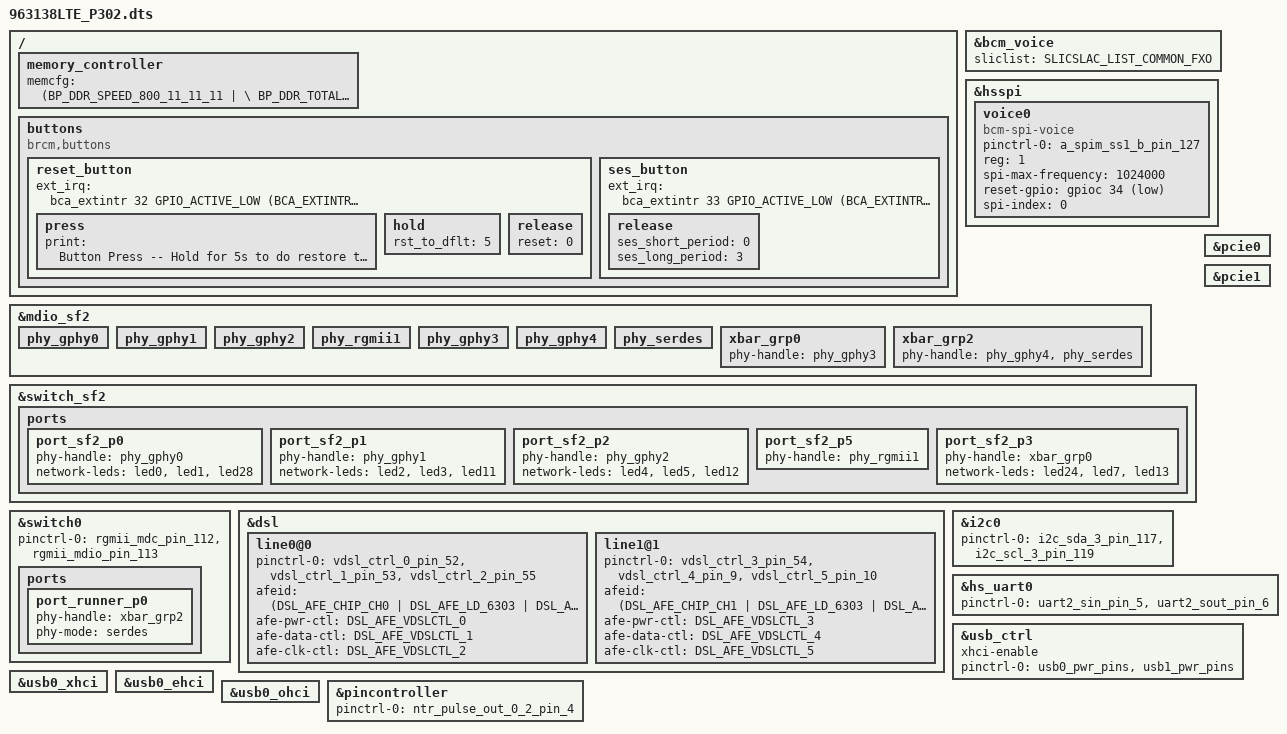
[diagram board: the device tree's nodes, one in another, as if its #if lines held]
#include "63138.dtsi"
#include "../bcm_voice.dtsi"
#include "963138LTE_leds.dtsi"

/ {
	memory_controller {
		memcfg = <(BP_DDR_SPEED_800_11_11_11   | \
			BP_DDR_TOTAL_SIZE_512MB  | \
			BP_DDR_DEVICE_WIDTH_16)>;
	};

	buttons {
		compatible = "brcm,buttons";
		reset_button {
			ext_irq = <&bca_extintr 32 GPIO_ACTIVE_LOW (BCA_EXTINTR_TYPE_LOW_LEVEL | BCA_EXTINTR_TYPE_SENSE_LEVEL)>;
			press {
				print = "Button Press -- Hold for 5s to do restore to default";
			};
			hold {
				rst_to_dflt = <5>;
			};
			release {
				reset = <0>;
			};	
		};
		ses_button {
			ext_irq = <&bca_extintr 33 GPIO_ACTIVE_LOW (BCA_EXTINTR_TYPE_LOW_LEVEL | BCA_EXTINTR_TYPE_SENSE_LEVEL)>;
			release {
				ses_short_period = <0>;
				ses_long_period = <3>;
			};
		};
	};
};

&bcm_voice{
	sliclist = SLICSLAC_LIST_COMMON_FXO;
 };

&hsspi {
	status = "okay";
	voice0 {
		pinctrl-0 = <&a_spim_ss1_b_pin_127>;
		pinctrl-names = "default";
		compatible = "bcm-spi-voice";
		reg = <1>; /* chip select 1 */
		spi-max-frequency = <1024000>;
		reset-gpio = <&gpioc 34 GPIO_ACTIVE_LOW>;
		spi-index = <0>;/* voice header index */
	};
};


&mdio_sf2 {
       /* Port PHY mapping:
            port_runner_p1  <-->  port_sf2_p8 -###- port_sf2_p0 <------------------> phy_gphy0
                                               # #- port_sf2_p1 <------------------> phy_gphy1
                                               # #- port_sf2_p2 <------------------> phy_gphy2
                                               # #- port_sf2_p5 <------------------> phy_rgmii1
                                               ###- port_sf2_p3 <--> xbar_grp0 -+-+- phy_gphy3
                                                 port_runner_p0 <--> xbar_grp2 -+-+- phy_gphy4
                                                                                  +- phy_serdes
         */
	/* PHYs directly connected to SF2 */
	phy_gphy0 {
		status = "okay";
	};
	phy_gphy1 {
		status = "okay";
	};
	phy_gphy2 {
		status = "okay";
	};
	phy_rgmii1 {
		status = "okay";
	};

	/* PHYs connected to crossbar */
	phy_gphy3 {
		status = "okay";
	};
	phy_gphy4 {
		status = "okay";
	};
	phy_serdes {
		status = "okay";
	};

	/* Crossbar groups */
	xbar_grp0 {
		phy-handle = <&phy_gphy3>;
		status = "okay";
	};
	xbar_grp2 {
		phy-handle = <&phy_gphy4 &phy_serdes>;
		status = "okay";
	};
};

&switch_sf2 {
	ports {
		/* ports connect directly */
		port_sf2_p0 {
			phy-handle = <&phy_gphy0>;
			network-leds = <&led0 &led1 &led28>;
			status = "okay";
		};

		port_sf2_p1 {
			phy-handle = <&phy_gphy1>;
			network-leds = <&led2 &led3 &led11>;
			status = "okay";
		};

		port_sf2_p2 {
			phy-handle = <&phy_gphy2>;
			network-leds = <&led4 &led5 &led12>;
			status = "okay";
		};

		port_sf2_p5 {
			phy-handle = <&phy_rgmii1>;
			status = "okay";
		};

		/* ports connected to crossbar */
		port_sf2_p3 {
			phy-handle = <&xbar_grp0>;
			network-leds = <&led24 &led7 &led13>;
			status = "okay";
		};
	};
};

&switch0 {
	pinctrl-names = "default"; 
	pinctrl-0 = <&rgmii_mdc_pin_112 &rgmii_mdio_pin_113>; 

	ports {
		
		port_runner_p0 {
			phy-handle = <&xbar_grp2>;
			phy-mode = "serdes";
			status = "okay";
		};
	};
};

&dsl {
	line0@0 {
		pinctrl-0 = <&vdsl_ctrl_0_pin_52 &vdsl_ctrl_1_pin_53 &vdsl_ctrl_2_pin_55>;
		pinctrl-names = "default";

		afeid = <(DSL_AFE_CHIP_CH0 | DSL_AFE_LD_6303 | DSL_AFE_FE_ANNEXA | DSL_AFE_FE_REV_6303_REV_12_3_40)>;
		afe-pwr-ctl = <DSL_AFE_VDSLCTL_0>;
		afe-data-ctl = <DSL_AFE_VDSLCTL_1>;
		afe-clk-ctl = <DSL_AFE_VDSLCTL_2>;
		status = "okay";
	};

	line1@1 {
		pinctrl-0 = <&vdsl_ctrl_3_pin_54 &vdsl_ctrl_4_pin_9 &vdsl_ctrl_5_pin_10>;
		pinctrl-names = "default";

		afeid = <(DSL_AFE_CHIP_CH1 | DSL_AFE_LD_6303 | DSL_AFE_FE_ANNEXA | DSL_AFE_FE_REV_6303_REV_12_3_40)>;
		afe-pwr-ctl = <DSL_AFE_VDSLCTL_3>;
		afe-data-ctl = <DSL_AFE_VDSLCTL_4>;
		afe-clk-ctl = <DSL_AFE_VDSLCTL_5>;
		status = "okay";
	};
};

#if defined(CONFIG_BCM_PCIE_HCD) || defined(CONFIG_BCM_PCIE_HCD_MODULE)
&pcie0 {
	status = "okay";
};
&pcie1 {
	status = "okay";
};
#endif //#if defined(CONFIG_BCM_PCIE_HCD) || defined(CONFIG_BCM_PCIE_HCD_MODULE)

&i2c0 {
	pinctrl-names = "default";
	pinctrl-0 = <&i2c_sda_3_pin_117 &i2c_scl_3_pin_119>;
};

&hs_uart0 {
	status = "okay";
	pinctrl-names = "default";
	pinctrl-0 = <&uart2_sin_pin_5 &uart2_sout_pin_6>;
};

&usb_ctrl {
	status = "okay";
	xhci-enable;
	pinctrl-names = "default";
	pinctrl-0 = <&usb0_pwr_pins &usb1_pwr_pins>;
};

&usb0_xhci {
	status = "okay";
};

&usb0_ehci {
	status = "okay";
};

&usb0_ohci {
	status = "okay";
};

&pincontroller {
	pinctrl-names = "default";
	pinctrl-0 = <&ntr_pulse_out_0_2_pin_4>;
};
